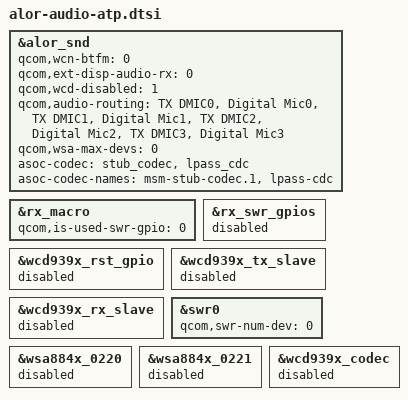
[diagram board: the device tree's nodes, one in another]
//
/* Copyright (c) Qualcomm Technologies, Inc. and/or its subsidiaries.
 *  SPDX-License-Identifier: BSD-3-Clause-Clear
 */
#include "alor-audio-cdp.dtsi"

&alor_snd {
	qcom,wcn-btfm = <0>;
	qcom,ext-disp-audio-rx = <0>;
	qcom,wcd-disabled =<1>;
	qcom,audio-routing =
		"TX DMIC0", "Digital Mic0",
		"TX DMIC1", "Digital Mic1",
		"TX DMIC2", "Digital Mic2",
		"TX DMIC3", "Digital Mic3";
	qcom,wsa-max-devs = <0>;
	asoc-codec  = <&stub_codec>, <&lpass_cdc>;
	asoc-codec-names = "msm-stub-codec.1", "lpass-cdc";
};

&rx_macro {
	qcom,is-used-swr-gpio = <0>;
};

&rx_swr_gpios {
	status = "disabled";
};

&wcd939x_rst_gpio {
	status = "disabled";
};

&wcd939x_tx_slave {
	status = "disabled";
};

&wcd939x_rx_slave {
	status = "disabled";
};

&swr0 {
	qcom,swr-num-dev = <0>;
};

&wsa884x_0220 {
	status = "disabled";
};

&wsa884x_0221 {
	status = "disabled";
};

&wcd939x_codec {
	status = "disabled";
};

